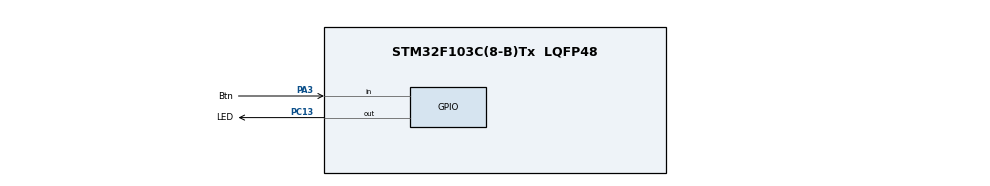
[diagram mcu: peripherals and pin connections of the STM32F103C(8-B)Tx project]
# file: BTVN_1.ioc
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Mcu.Family=STM32F1
Mcu.Name=STM32F103C(8-B)Tx
Mcu.Package=LQFP48
NVIC.PriorityGroup=NVIC_PRIORITYGROUP_4
PA13.Mode=Serial_Wire
PA13.Signal=SYS_JTMS-SWDIO
PA14.Mode=Serial_Wire
PA14.Signal=SYS_JTCK-SWCLK
PA3.GPIO_Label=Btn
PA3.GPIO_PuPd=GPIO_PULLUP
PA3.Signal=GPIO_Input
PC13-TAMPER-RTC.GPIO_Label=LED
PC13-TAMPER-RTC.Signal=GPIO_Output
PD0-OSC_IN.Mode=HSE-External-Oscillator
PD0-OSC_IN.Signal=RCC_OSC_IN
PD1-OSC_OUT.Mode=HSE-External-Oscillator
PD1-OSC_OUT.Signal=RCC_OSC_OUT
ProjectManager.HeapSize=0x200
ProjectManager.StackSize=0x400
ProjectManager.TargetToolchain=STM32CubeIDE
RCC.AHBFreq_Value=40000000
RCC.APB1CLKDivider=RCC_HCLK_DIV2
RCC.APB1Freq_Value=20000000
RCC.APB1TimFreq_Value=40000000
RCC.APB2Freq_Value=40000000
RCC.APB2TimFreq_Value=40000000
RCC.HCLKFreq_Value=40000000
RCC.PLLMUL=RCC_PLL_MUL5
RCC.PLLSourceVirtual=RCC_PLLSOURCE_HSE
RCC.SYSCLKFreq_VALUE=40000000
RCC.SYSCLKSource=RCC_SYSCLKSOURCE_PLLCLK
RCC.USBFreq_Value=40000000
board=custom

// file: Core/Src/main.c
/* USER CODE BEGIN Header */
/**
  ******************************************************************************
  * @file           : main.c
  * @brief          : Main program body
  ******************************************************************************
  * @attention
  *
  * Copyright (c) 2024 STMicroelectronics.
  * All rights reserved.
  *
  * This software is licensed under terms that can be found in the LICENSE file
  * in the root directory of this software component.
  * If no LICENSE file comes with this software, it is provided AS-IS.
  *
  ******************************************************************************
  */
/* USER CODE END Header */
#include "main.h"

/* USER CODE BEGIN Includes */
#include "task.h"
/* USER CODE END Includes */

void SystemClock_Config(void);
static void MX_GPIO_Init(void);

int main(void)
{

  /* MCU Configuration--------------------------------------------------------*/

  /* Reset of all peripherals, Initializes the Flash interface and the Systick. */
  LL_APB2_GRP1_EnableClock(LL_APB2_GRP1_PERIPH_AFIO);
  LL_APB1_GRP1_EnableClock(LL_APB1_GRP1_PERIPH_PWR);

  /* System interrupt init*/
  NVIC_SetPriorityGrouping(NVIC_PRIORITYGROUP_4);

  /* SysTick_IRQn interrupt configuration */
  NVIC_SetPriority(SysTick_IRQn, NVIC_EncodePriority(NVIC_GetPriorityGrouping(),15, 0));

  /** NOJTAG: JTAG-DP Disabled and SW-DP Enabled
  */
  LL_GPIO_AF_Remap_SWJ_NOJTAG();

  /* Configure the system clock */
  SystemClock_Config();

  /* Initialize all configured peripherals */
  MX_GPIO_Init();
  /* USER CODE BEGIN 2 */
  LL_SYSTICK_EnableIT();
  led_init_state();
  /* USER CODE END 2 */

  /* Infinite loop */
  while (1)
  {
	  led_state_update();
  }
}

void SystemClock_Config(void)
{
  LL_FLASH_SetLatency(LL_FLASH_LATENCY_1);
  while(LL_FLASH_GetLatency()!= LL_FLASH_LATENCY_1)
  {
  }
  LL_RCC_HSE_Enable();

   /* Wait till HSE is ready */
  while(LL_RCC_HSE_IsReady() != 1)
  {

  }
  LL_RCC_PLL_ConfigDomain_SYS(LL_RCC_PLLSOURCE_HSE_DIV_1, LL_RCC_PLL_MUL_5);
  LL_RCC_PLL_Enable();

   /* Wait till PLL is ready */
  while(LL_RCC_PLL_IsReady() != 1)
  {

  }
  LL_RCC_SetAHBPrescaler(LL_RCC_SYSCLK_DIV_1);
  LL_RCC_SetAPB1Prescaler(LL_RCC_APB1_DIV_2);
  LL_RCC_SetAPB2Prescaler(LL_RCC_APB2_DIV_1);
  LL_RCC_SetSysClkSource(LL_RCC_SYS_CLKSOURCE_PLL);

   /* Wait till System clock is ready */
  while(LL_RCC_GetSysClkSource() != LL_RCC_SYS_CLKSOURCE_STATUS_PLL)
  {

  }
  LL_Init1msTick(40000000);
  LL_SetSystemCoreClock(40000000);
}

static void MX_GPIO_Init(void)
{
  LL_GPIO_InitTypeDef GPIO_InitStruct = {0};

  /* GPIO Ports Clock Enable */
  LL_APB2_GRP1_EnableClock(LL_APB2_GRP1_PERIPH_GPIOC);
  LL_APB2_GRP1_EnableClock(LL_APB2_GRP1_PERIPH_GPIOD);
  LL_APB2_GRP1_EnableClock(LL_APB2_GRP1_PERIPH_GPIOA);

  /**/
  LL_GPIO_ResetOutputPin(LED_GPIO_Port, LED_Pin);

  /**/
  GPIO_InitStruct.Pin = LED_Pin;
  GPIO_InitStruct.Mode = LL_GPIO_MODE_OUTPUT;
  GPIO_InitStruct.Speed = LL_GPIO_SPEED_FREQ_LOW;
  GPIO_InitStruct.OutputType = LL_GPIO_OUTPUT_PUSHPULL;
  LL_GPIO_Init(LED_GPIO_Port, &GPIO_InitStruct);

  /**/
  GPIO_InitStruct.Pin = Btn_Pin;
  GPIO_InitStruct.Mode = LL_GPIO_MODE_INPUT;
  GPIO_InitStruct.Pull = LL_GPIO_PULL_UP;
  LL_GPIO_Init(Btn_GPIO_Port, &GPIO_InitStruct);

}

void Error_Handler(void)
{
  __disable_irq();
  while (1)
  {
  }
}
